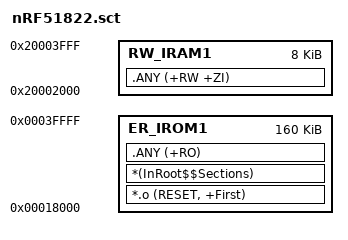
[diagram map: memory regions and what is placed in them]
;WITHOUT SOFTDEVICE:
;LR_IROM1 0x00000000 0x00040000  {
;  ER_IROM1 0x00000000 0x00040000  {
;   *.o (RESET, +First)
;   *(InRoot$$Sections)
;   .ANY (+RO)
;  }
;  RW_IRAM1 0x20000000 0x00004000  {
;   .ANY (+RW +ZI)
;  }
;}
;
;WITH SOFTDEVICE:

LR_IROM1 0x18000 0x0028000  {
  ER_IROM1 0x18000 0x0028000  {
   *.o (RESET, +First)
   *(InRoot$$Sections)
   .ANY (+RO)
  }
  RW_IRAM1 0x20002000 0x00002000  {
   .ANY (+RW +ZI)
  }
}
